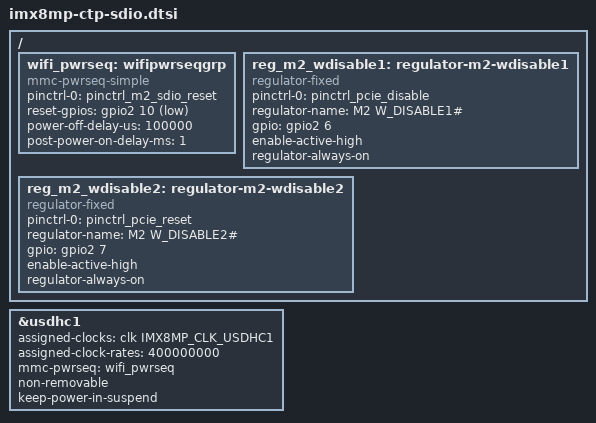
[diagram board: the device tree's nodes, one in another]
// SPDX-License-Identifier: LicenseRef-Ezurio-Clause
/*
 * Copyright 2024 Ezurio
 */

#include "imx8mp-ctp.dtsi"

/ {
	wifi_pwrseq: wifipwrseqgrp {
		pinctrl-names = "default";
		pinctrl-0 = <&pinctrl_m2_sdio_reset>;

		compatible = "mmc-pwrseq-simple";
		// M2_SD_nRST, SD1_RESET_B, ball W25
		reset-gpios = <&gpio2 10 GPIO_ACTIVE_LOW>;

		power-off-delay-us = <100000>;
		post-power-on-delay-ms = <1>;
	};

	reg_m2_wdisable1: regulator-m2-wdisable1 {
		pinctrl-names = "default";
		pinctrl-0 = <&pinctrl_pcie_disable>;

		compatible = "regulator-fixed";

		regulator-name = "M2 W_DISABLE1#";

		// W_DISABLE1# (WL_REG_ON, pin 56), SD1_DATA4, gpio2 6, ball U26
		// NOT connected on IF91x M.2 module; connected on DVK board
		gpio = <&gpio2 6 GPIO_ACTIVE_HIGH>;
		enable-active-high;
		regulator-always-on;
	};

	reg_m2_wdisable2: regulator-m2-wdisable2 {
		pinctrl-names = "default";
		pinctrl-0 = <&pinctrl_pcie_reset>;

		compatible = "regulator-fixed";

		regulator-name = "M2 W_DISABLE2#";

		// W_DISABLE2# (BT_REG_ON, pin 54), SD1_DATA5, gpio2 7, ball AA29
		// Drives IF91x MCU internal regulator on M.2 module
		gpio = <&gpio2 7 GPIO_ACTIVE_HIGH>;
		enable-active-high;
		regulator-always-on;
	};
};

&usdhc1 {
	status = "okay";

	assigned-clocks = <&clk IMX8MP_CLK_USDHC1>;
	assigned-clock-rates = <400000000>;

	mmc-pwrseq = <&wifi_pwrseq>;

	non-removable;
	keep-power-in-suspend;
};
